# adc_reva_me55 register map
Registers are 32-bit, read-write, no defined reset value unless marked. A register's access mark holds for its fields unless they carry their own. Offsets are from the block's base; lines under a group give offsets from that group; [hi:lo] are bit positions; {n}, {i} and the like mark numbered series; 'fields as' and 'values as' point back to an identical list; <NAME> marks a mode.

## Memory map
0x40034000 ADC size 0x1000 — 10-bit Analog to Digital Converter

## Interrupts
20 ADC — ADC IRQ

## ADC — 10-bit Analog to Digital Converter
Base 0x40034000
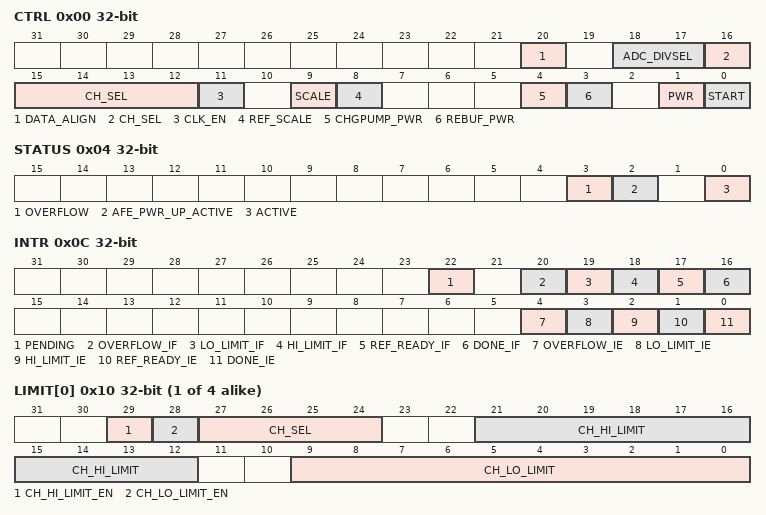
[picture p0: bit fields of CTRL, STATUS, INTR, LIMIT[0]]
0x00 CTRL — ADC Control
  [20] DATA_ALIGN — ADC Data Alignment Select
  [18:17] ADC_DIVSEL — Scales the external inputs, all inputs are scaled the same
    {v}=DIV{v+1} (v=0..3)
  [16:12] CH_SEL — ADC Channel Select
    {v}=AIN{v} (v=0..7); 8=VcoreA; 9=VcoreB; 10=Vrxout; 11=Vtxout; 12=VddA; 13=VddB/4; 14=Vddio/4; 15=Vddioh/4; 16=VregI/4
  [11] CLK_EN — ADC Clock Enable
  [9] SCALE — ADC Scale
  [8] REF_SCALE — ADC Reference Scale
  [4] CHGPUMP_PWR — ADC Charge Pump Power Up
  [3] REBUF_PWR — ADC Reference Buffer Power Up
  [1] PWR — ADC Power Up
  [0] START — Start ADC Conversion
0x04 STATUS — ADC Status
  [3] OVERFLOW ro — ADC Overflow
  [2] AFE_PWR_UP_ACTIVE ro — AFE Power Up Delay Active
  [0] ACTIVE ro — ADC Conversion In Progress
0x08 DATA — ADC Output Data
  [15:0] DATA ro — ADC Converted Sample Data Output
0x0C INTR — ADC Interrupt Control Register
  [22] PENDING ro — ADC Interrupt Pending Status
  [20] OVERFLOW_IF write-1-clears — ADC Overflow Interrupt Flag
  [19] LO_LIMIT_IF write-1-clears — ADC Lo Limit Monitor Interrupt Flag
  [18] HI_LIMIT_IF write-1-clears — ADC Hi Limit Monitor Interrupt Flag
  [17] REF_READY_IF write-1-clears — ADC Reference Ready Interrupt Flag
  [16] DONE_IF write-1-clears — ADC Done Interrupt Flag
  [4] OVERFLOW_IE — ADC Overflow Interrupt Enable
  [3] LO_LIMIT_IE — ADC Lo Limit Monitor Interrupt Enable
  [2] HI_LIMIT_IE — ADC Hi Limit Monitor Interrupt Enable
  [1] REF_READY_IE — ADC Reference Ready Interrupt Enable
  [0] DONE_IE — ADC Done Interrupt Enable
{0x10+4i} LIMIT[{i}] (i=0..3) — ADC Limit
  [29] CH_HI_LIMIT_EN — High Limit Monitoring Enable
  [28] CH_LO_LIMIT_EN — Low Limit Monitoring Enable
  [27:24] CH_SEL — ADC Channel Select
  [21:12] CH_HI_LIMIT — High Limit Threshold
  [9:0] CH_LO_LIMIT — Low Limit Threshold
0x20 DECCNT — ADC Decimation Count.
  [31:0] DELAY
